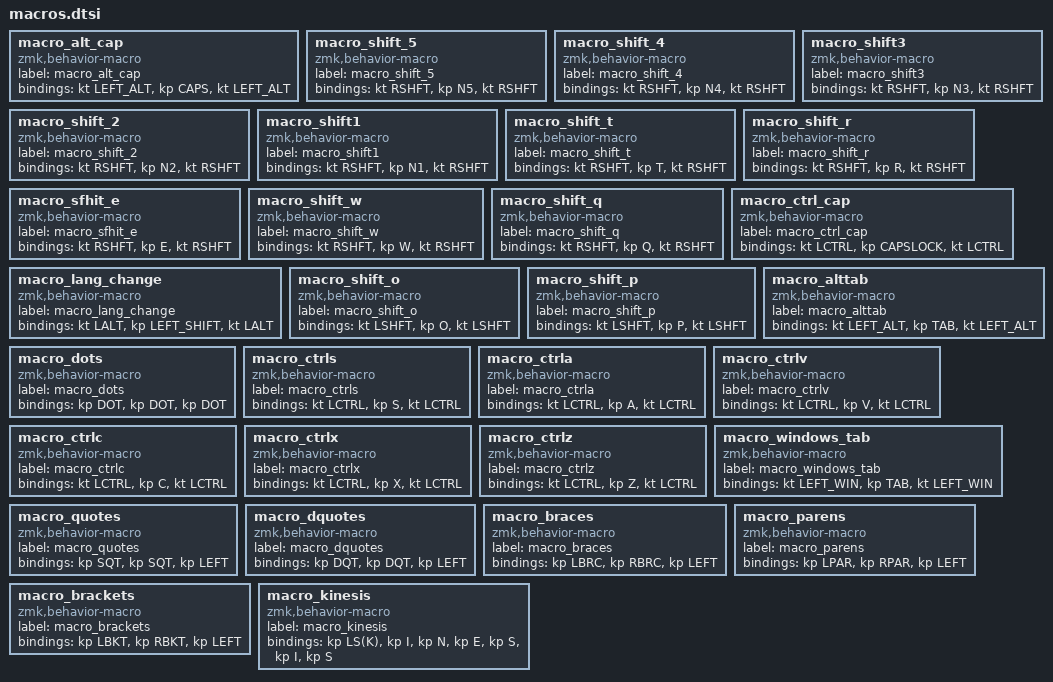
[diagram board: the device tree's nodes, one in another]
macro_alt_cap: macro_alt_cap{
compatible = "zmk,behavior-macro";
label = "macro_alt_cap";
#binding-cells = <0>;
bindings = <&kt LEFT_ALT>, <&kp CAPS>, <&kt LEFT_ALT>;
};
macro_shift_5: macro_shift_5{
compatible = "zmk,behavior-macro";
label = "macro_shift_5";
#binding-cells = <0>;
bindings = <&kt RSHFT>, <&kp N5>, <&kt RSHFT>;
};
macro_shift_4: macro_shift_4{
compatible = "zmk,behavior-macro";
label = "macro_shift_4";
#binding-cells = <0>;
bindings = <&kt RSHFT>, <&kp N4>, <&kt RSHFT>;
};
macro_shift3: macro_shift3{
compatible = "zmk,behavior-macro";
label = "macro_shift3";
#binding-cells = <0>;
bindings = <&kt RSHFT>, <&kp N3>, <&kt RSHFT>;
};
macro_shift_2: macro_shift_2{
compatible = "zmk,behavior-macro";
label = "macro_shift_2";
#binding-cells = <0>;
bindings = <&kt RSHFT>, <&kp N2>, <&kt RSHFT>;
};
macro_shift1: macro_shift1{
compatible = "zmk,behavior-macro";
label = "macro_shift1";
#binding-cells = <0>;
bindings = <&kt RSHFT>, <&kp N1>, <&kt RSHFT>;
};
macro_shift_t: macro_shift_t{
compatible = "zmk,behavior-macro";
label = "macro_shift_t";
#binding-cells = <0>;
bindings = <&kt RSHFT>, <&kp T>, <&kt RSHFT>;
};
macro_shift_r: macro_shift_r{
compatible = "zmk,behavior-macro";
label = "macro_shift_r";
#binding-cells = <0>;
bindings = <&kt RSHFT>, <&kp R>, <&kt RSHFT>;
};
macro_sfhit_e: macro_sfhit_e{
compatible = "zmk,behavior-macro";
label = "macro_sfhit_e";
#binding-cells = <0>;
bindings = <&kt RSHFT>, <&kp E>, <&kt RSHFT>;
};
macro_shift_w: macro_shift_w{
compatible = "zmk,behavior-macro";
label = "macro_shift_w";
#binding-cells = <0>;
bindings = <&kt RSHFT>, <&kp W>, <&kt RSHFT>;
};
macro_shift_q: macro_shift_q{
compatible = "zmk,behavior-macro";
label = "macro_shift_q";
#binding-cells = <0>;
bindings = <&kt RSHFT>, <&kp Q>, <&kt RSHFT>;
};
macro_ctrl_cap: macro_ctrl_cap{
compatible = "zmk,behavior-macro";
label = "macro_ctrl_cap";
#binding-cells = <0>;
bindings = <&kt LCTRL>, <&kp CAPSLOCK>, <&kt LCTRL>;
};
macro_lang_change: macro_lang_change{
compatible = "zmk,behavior-macro";
label = "macro_lang_change";
#binding-cells = <0>;
bindings = <&kt LALT>, <&kp LEFT_SHIFT>, <&kt LALT>;
};
macro_shift_o: macro_shift_o{
compatible = "zmk,behavior-macro";
label = "macro_shift_o";
#binding-cells = <0>;
bindings = <&kt LSHFT>, <&kp O>, <&kt LSHFT>;
};
macro_shift_p: macro_shift_p{
compatible = "zmk,behavior-macro";
label = "macro_shift_p";
#binding-cells = <0>;
bindings = <&kt LSHFT>, <&kp P>, <&kt LSHFT>;
};
macro_alttab: macro_alttab{
compatible = "zmk,behavior-macro";
label = "macro_alttab";
#binding-cells = <0>;
bindings = <&kt LEFT_ALT>, <&kp TAB>, <&kt LEFT_ALT>;
};
macro_dots: macro_dots{
compatible = "zmk,behavior-macro";
label = "macro_dots";
#binding-cells = <0>;
bindings = <&kp DOT>, <&kp DOT>, <&kp DOT>;
};
macro_ctrls: macro_ctrls{
compatible = "zmk,behavior-macro";
label = "macro_ctrls";
#binding-cells = <0>;
bindings = <&kt LCTRL>, <&kp S>, <&kt LCTRL>;
};
macro_ctrla: macro_ctrla{
compatible = "zmk,behavior-macro";
label = "macro_ctrla";
#binding-cells = <0>;
bindings = <&kt LCTRL>, <&kp A>, <&kt LCTRL>;
};
macro_ctrlv: macro_ctrlv{
compatible = "zmk,behavior-macro";
label = "macro_ctrlv";
#binding-cells = <0>;
bindings = <&kt LCTRL>, <&kp V>, <&kt LCTRL>;
};
macro_ctrlc: macro_ctrlc{
compatible = "zmk,behavior-macro";
label = "macro_ctrlc";
#binding-cells = <0>;
bindings = <&kt LCTRL>, <&kp C>, <&kt LCTRL>;
};
macro_ctrlx: macro_ctrlx{
compatible = "zmk,behavior-macro";
label = "macro_ctrlx";
#binding-cells = <0>;
bindings = <&kt LCTRL>, <&kp X>, <&kt LCTRL>;
};
macro_ctrlz: macro_ctrlz{
compatible = "zmk,behavior-macro";
label = "macro_ctrlz";
#binding-cells = <0>;
bindings = <&kt LCTRL>, <&kp Z>, <&kt LCTRL>;
};
macro_windows_tab: macro_windows_tab{
compatible = "zmk,behavior-macro";
label = "macro_windows_tab";
#binding-cells = <0>;
bindings = <&kt LEFT_WIN>, <&kp TAB>, <&kt LEFT_WIN>;
};
macro_quotes: macro_quotes{
compatible = "zmk,behavior-macro";
label = "macro_quotes";
#binding-cells = <0>;
bindings = <&kp SQT>, <&kp SQT>, <&kp LEFT>;
};
macro_dquotes: macro_dquotes{
compatible = "zmk,behavior-macro";
label = "macro_dquotes";
#binding-cells = <0>;
bindings = <&kp DQT>, <&kp DQT>, <&kp LEFT>;
};
macro_braces: macro_braces{
compatible = "zmk,behavior-macro";
label = "macro_braces";
#binding-cells = <0>;
bindings = <&kp LBRC>, <&kp RBRC>, <&kp LEFT>;
};
macro_parens: macro_parens{
compatible = "zmk,behavior-macro";
label = "macro_parens";
#binding-cells = <0>;
bindings = <&kp LPAR>, <&kp RPAR>, <&kp LEFT>;
};
macro_brackets: macro_brackets{
compatible = "zmk,behavior-macro";
label = "macro_brackets";
#binding-cells = <0>;
bindings = <&kp LBKT>, <&kp RBKT>, <&kp LEFT>;
};
macro_kinesis: macro_kinesis{
compatible = "zmk,behavior-macro";
label = "macro_kinesis";
#binding-cells = <0>;
bindings = <&kp LS(K)>, <&kp I>, <&kp N>, <&kp E>, <&kp S>, <&kp I>, <&kp S>;
};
